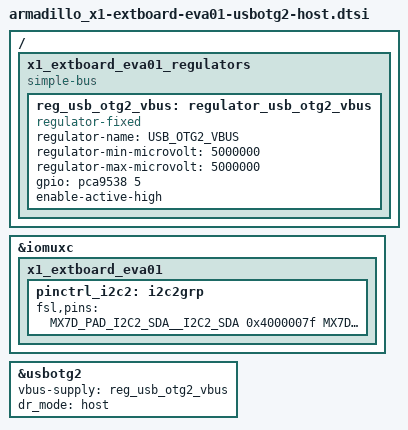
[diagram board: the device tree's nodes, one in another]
/*
 * Copyright (C) 2018 Atmark Techno, Inc. All Rights Reserved.
 *
 * This program is free software; you can redistribute it and/or modify
 * it under the terms of the GNU General Public License version 2 as
 * published by the Free Software Foundation.
 */

/ {
	x1_extboard_eva01_regulators {
		compatible = "simple-bus";
		#address-cells = <1>;
		#size-cells = <0>;

		reg_usb_otg2_vbus: regulator_usb_otg2_vbus {
			compatible = "regulator-fixed";
			regulator-name = "USB_OTG2_VBUS";
			regulator-min-microvolt = <5000000>;
			regulator-max-microvolt = <5000000>;
			gpio = <&pca9538 5 GPIO_ACTIVE_HIGH>;
			enable-active-high;
		};
	};
};

&iomuxc {
	x1_extboard_eva01 {
		pinctrl_i2c2: i2c2grp {
			fsl,pins = <
				MX7D_PAD_I2C2_SDA__I2C2_SDA	0x4000007f
				MX7D_PAD_I2C2_SCL__I2C2_SCL	0x4000007f
			>;
		};
	};
};

&usbotg2 {
	vbus-supply = <&reg_usb_otg2_vbus>;
	dr_mode = "host";
	status = "okay";
};
